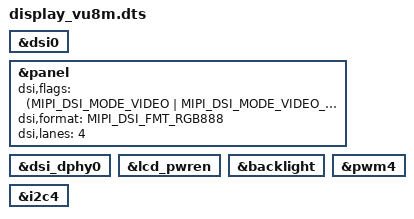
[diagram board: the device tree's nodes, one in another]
/dts-v1/;
/plugin/;

#include <dt-bindings/display/drm_mipi_dsi.h>

/{
	fragment@0 {
		target = <&dsi0>;

		__overlay__ {
			status = "okay";
		};
	};

	fragment@1 {
		target = <&panel>;

		__overlay__ {
			status = "okay";

			dsi,flags = <(MIPI_DSI_MODE_VIDEO | MIPI_DSI_MODE_VIDEO_BURST)>;
			dsi,format = <MIPI_DSI_FMT_RGB888>;
			dsi,lanes = <4>;
		};
	};

	fragment@2 {
		target = <&dsi_dphy0>;

		__overlay__ {
			status = "okay";
		};
	};

	fragment@3 {
		target = <&lcd_pwren>;

		__overlay__ {
			status = "okay";
		};
	};

	fragment@4 {
		target = <&backlight>;

		__overlay__ {
			status = "okay";
		};
	};

	fragment@5 {
		target = <&pwm4>;

		__overlay__ {
			status = "okay";
		};
	};

	fragment@6 {
		target = <&i2c4>;

		__overlay__ {
			status = "okay";
		};
	};
};
